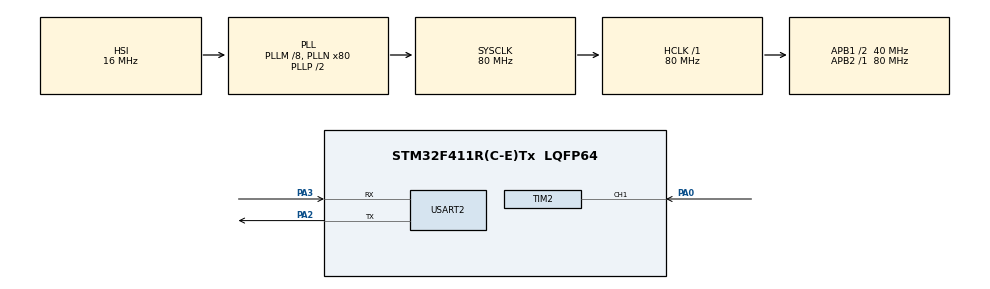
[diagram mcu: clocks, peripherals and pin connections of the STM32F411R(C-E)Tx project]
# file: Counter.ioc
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Mcu.Family=STM32F4
Mcu.Name=STM32F411R(C-E)Tx
Mcu.Package=LQFP64
NVIC.PriorityGroup=NVIC_PRIORITYGROUP_4
NVIC.TIM2_IRQn=true\:0\:0\:false\:false\:true\:true\:true\:true
PA0-WKUP.Signal=S_TIM2_CH1_ETR
PA2.Mode=Asynchronous
PA2.Signal=USART2_TX
PA3.Mode=Asynchronous
PA3.Signal=USART2_RX
ProjectManager.HeapSize=0x200
ProjectManager.StackSize=0x400
ProjectManager.TargetToolchain=STM32CubeIDE
RCC.48MHZClocksFreq_Value=40000000
RCC.AHBFreq_Value=80000000
RCC.APB1CLKDivider=RCC_HCLK_DIV2
RCC.APB1Freq_Value=40000000
RCC.APB1TimFreq_Value=80000000
RCC.APB2Freq_Value=80000000
RCC.APB2TimFreq_Value=80000000
RCC.CortexFreq_Value=80000000
RCC.HCLKFreq_Value=80000000
RCC.HSE_VALUE=25000000
RCC.HSI_VALUE=16000000
RCC.LSE_VALUE=32768
RCC.PLLM=8
RCC.PLLN=80
RCC.SYSCLKFreq_VALUE=80000000
RCC.SYSCLKSource=RCC_SYSCLKSOURCE_PLLCLK
RCC.VCOOutputFreq_Value=160000000
SH.S_TIM2_CH1_ETR.0=TIM2_CH1,Input_Capture1_from_TI1
TIM2.Channel-Input_Capture1_from_TI1=TIM_CHANNEL_1
TIM2.Period=65535
USART2.VirtualMode=VM_ASYNC
board=custom

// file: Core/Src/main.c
/* USER CODE BEGIN Header */
/**
  ******************************************************************************
  * @file           : main.c
  * @brief          : Main program body
  ******************************************************************************
  * @attention
  *
  * Copyright (c) 2022 STMicroelectronics.
  * All rights reserved.
  *
  * This software is licensed under terms that can be found in the LICENSE file
  * in the root directory of this software component.
  * If no LICENSE file comes with this software, it is provided AS-IS.
  *
  ******************************************************************************
  */
/* USER CODE END Header */
#include "main.h"

TIM_HandleTypeDef htim2;

UART_HandleTypeDef huart2;

void SystemClock_Config(void);
static void MX_GPIO_Init(void);
static void MX_USART2_UART_Init(void);
static void MX_TIM2_Init(void);

int main(void)
{
  /* USER CODE BEGIN 1 */
	  uint8_t MSG[35] = {'\0'};
	  uint16_t X = 0;
  /* USER CODE END 1 */

  /* MCU Configuration--------------------------------------------------------*/

  /* Reset of all peripherals, Initializes the Flash interface and the Systick. */
  HAL_Init();

  /* Configure the system clock */
  SystemClock_Config();

  /* Initialize all configured peripherals */
  MX_GPIO_Init();
  MX_USART2_UART_Init();
  MX_TIM2_Init();

  /* Infinite loop */
  /* USER CODE BEGIN WHILE */
  while (1)
  {

	 sprintf(MSG, "Hello Dudes! Tracing X = %d\r\n", X);
	 HAL_UART_Transmit(&huart2, MSG, sizeof(MSG), 100);
	 HAL_Delay(1);
	 X++;
    /* USER CODE END WHILE */

  }
}

void SystemClock_Config(void)
{
  RCC_OscInitTypeDef RCC_OscInitStruct = {0};
  RCC_ClkInitTypeDef RCC_ClkInitStruct = {0};

  /** Configure the main internal regulator output voltage
  */
  __HAL_RCC_PWR_CLK_ENABLE();
  __HAL_PWR_VOLTAGESCALING_CONFIG(PWR_REGULATOR_VOLTAGE_SCALE1);

  /** Initializes the RCC Oscillators according to the specified parameters
  * in the RCC_OscInitTypeDef structure.
  */
  RCC_OscInitStruct.OscillatorType = RCC_OSCILLATORTYPE_HSI;
  RCC_OscInitStruct.HSIState = RCC_HSI_ON;
  RCC_OscInitStruct.HSICalibrationValue = RCC_HSICALIBRATION_DEFAULT;
  RCC_OscInitStruct.PLL.PLLState = RCC_PLL_ON;
  RCC_OscInitStruct.PLL.PLLSource = RCC_PLLSOURCE_HSI;
  RCC_OscInitStruct.PLL.PLLM = 8;
  RCC_OscInitStruct.PLL.PLLN = 80;
  RCC_OscInitStruct.PLL.PLLP = RCC_PLLP_DIV2;
  RCC_OscInitStruct.PLL.PLLQ = 4;
  if (HAL_RCC_OscConfig(&RCC_OscInitStruct) != HAL_OK)
  {
    Error_Handler();
  }

  /** Initializes the CPU, AHB and APB buses clocks
  */
  RCC_ClkInitStruct.ClockType = RCC_CLOCKTYPE_HCLK|RCC_CLOCKTYPE_SYSCLK
                              |RCC_CLOCKTYPE_PCLK1|RCC_CLOCKTYPE_PCLK2;
  RCC_ClkInitStruct.SYSCLKSource = RCC_SYSCLKSOURCE_PLLCLK;
  RCC_ClkInitStruct.AHBCLKDivider = RCC_SYSCLK_DIV1;
  RCC_ClkInitStruct.APB1CLKDivider = RCC_HCLK_DIV2;
  RCC_ClkInitStruct.APB2CLKDivider = RCC_HCLK_DIV1;

  if (HAL_RCC_ClockConfig(&RCC_ClkInitStruct, FLASH_LATENCY_2) != HAL_OK)
  {
    Error_Handler();
  }
}

static void MX_TIM2_Init(void)
{

  TIM_MasterConfigTypeDef sMasterConfig = {0};
  TIM_IC_InitTypeDef sConfigIC = {0};

  htim2.Instance = TIM2;
  htim2.Init.Prescaler = 0;
  htim2.Init.CounterMode = TIM_COUNTERMODE_UP;
  htim2.Init.Period = 65535;
  htim2.Init.ClockDivision = TIM_CLOCKDIVISION_DIV1;
  htim2.Init.AutoReloadPreload = TIM_AUTORELOAD_PRELOAD_DISABLE;
  if (HAL_TIM_IC_Init(&htim2) != HAL_OK)
  {
    Error_Handler();
  }
  sMasterConfig.MasterOutputTrigger = TIM_TRGO_RESET;
  sMasterConfig.MasterSlaveMode = TIM_MASTERSLAVEMODE_DISABLE;
  if (HAL_TIMEx_MasterConfigSynchronization(&htim2, &sMasterConfig) != HAL_OK)
  {
    Error_Handler();
  }
  sConfigIC.ICPolarity = TIM_INPUTCHANNELPOLARITY_RISING;
  sConfigIC.ICSelection = TIM_ICSELECTION_DIRECTTI;
  sConfigIC.ICPrescaler = TIM_ICPSC_DIV1;
  sConfigIC.ICFilter = 0;
  if (HAL_TIM_IC_ConfigChannel(&htim2, &sConfigIC, TIM_CHANNEL_1) != HAL_OK)
  {
    Error_Handler();
  }

}

static void MX_USART2_UART_Init(void)
{

  huart2.Instance = USART2;
  huart2.Init.BaudRate = 115200;
  huart2.Init.WordLength = UART_WORDLENGTH_8B;
  huart2.Init.StopBits = UART_STOPBITS_1;
  huart2.Init.Parity = UART_PARITY_NONE;
  huart2.Init.Mode = UART_MODE_TX_RX;
  huart2.Init.HwFlowCtl = UART_HWCONTROL_NONE;
  huart2.Init.OverSampling = UART_OVERSAMPLING_16;
  if (HAL_UART_Init(&huart2) != HAL_OK)
  {
    Error_Handler();
  }

}

static void MX_GPIO_Init(void)
{

  /* GPIO Ports Clock Enable */
  __HAL_RCC_GPIOA_CLK_ENABLE();

}

void Error_Handler(void)
{
  __disable_irq();
  while (1)
  {
  }
}
